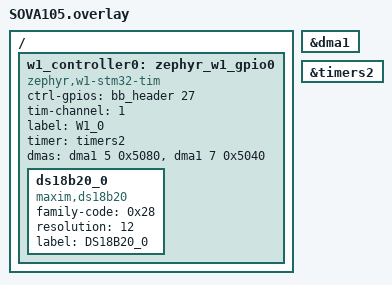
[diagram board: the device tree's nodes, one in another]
/ {
	w1_controller0: zephyr_w1_gpio0 {
		compatible = "zephyr,w1-stm32-tim";
		ctrl-gpios = <&bb_header 27 0>;
		tim-channel = <1>;
		label = "W1_0";
		timer = <&timers2>;
		dmas = <&dma1 5 0x5080>,
			   <&dma1 7 0x5040>;
		dma-names = "rx", "tx";

		status = "okay";


		ds18b20_0: ds18b20_0 {
			compatible = "maxim,ds18b20";
			family-code = <0x28>;
			resolution = <12>;
			label = "DS18B20_0";
			status = "okay";
		};
	};
};

&dma1 {
	status = "okay";
};
&timers2 {
	status = "okay";
};
